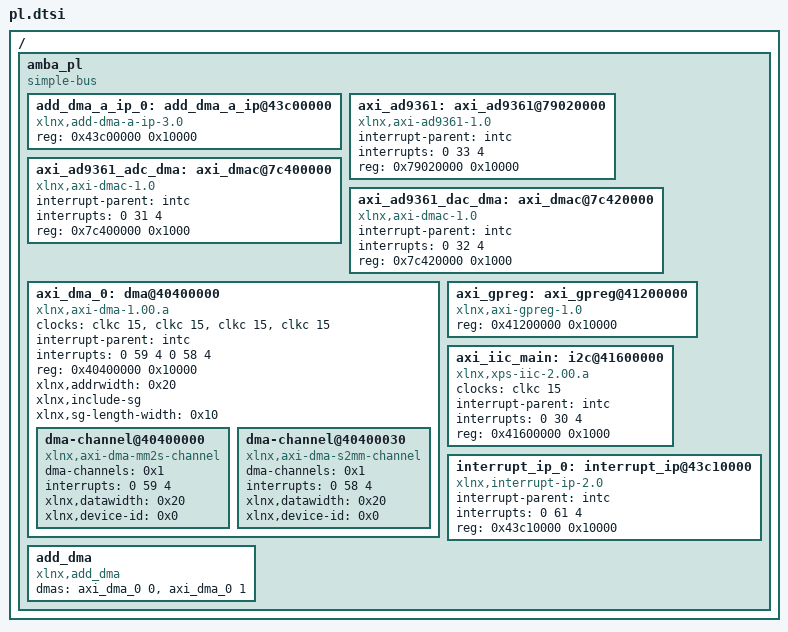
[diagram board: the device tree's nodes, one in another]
/*
 * CAUTION: This file is automatically generated by Xilinx.
 * Version:  
 * Today is: Mon May 18 16:09:08 2020
 */


/ {
	amba_pl: amba_pl {
		#address-cells = <1>;
		#size-cells = <1>;
		compatible = "simple-bus";
		ranges ;
		add_dma_a_ip_0: add_dma_a_ip@43c00000 {
			compatible = "xlnx,add-dma-a-ip-3.0";
			reg = <0x43c00000 0x10000>;
		};
		axi_ad9361: axi_ad9361@79020000 {
			compatible = "xlnx,axi-ad9361-1.0";
			interrupt-names = "gps_pps_irq";
			interrupt-parent = <&intc>;
			interrupts = <0 33 4>;
			reg = <0x79020000 0x10000>;
		};
		axi_ad9361_adc_dma: axi_dmac@7c400000 {
			compatible = "xlnx,axi-dmac-1.0";
			interrupt-names = "irq";
			interrupt-parent = <&intc>;
			interrupts = <0 31 4>;
			reg = <0x7c400000 0x1000>;
		};
		axi_ad9361_dac_dma: axi_dmac@7c420000 {
			compatible = "xlnx,axi-dmac-1.0";
			interrupt-names = "irq";
			interrupt-parent = <&intc>;
			interrupts = <0 32 4>;
			reg = <0x7c420000 0x1000>;
		};
		axi_dma_0: dma@40400000 {
			#dma-cells = <1>;
			clock-names = "s_axi_lite_aclk", "m_axi_sg_aclk", "m_axi_mm2s_aclk", "m_axi_s2mm_aclk";
			clocks = <&clkc 15>, <&clkc 15>, <&clkc 15>, <&clkc 15>;
			compatible = "xlnx,axi-dma-1.00.a";
			interrupt-names = "mm2s_introut", "s2mm_introut";
			interrupt-parent = <&intc>;
			interrupts = <0 59 4 0 58 4>;
			reg = <0x40400000 0x10000>;
			xlnx,addrwidth = <0x20>;
			xlnx,include-sg ;
			xlnx,sg-length-width = <0x10>;
			dma-channel@40400000 {
				compatible = "xlnx,axi-dma-mm2s-channel";
				dma-channels = <0x1>;
				interrupts = <0 59 4>;
				xlnx,datawidth = <0x20>;
				xlnx,device-id = <0x0>;
			};
			dma-channel@40400030 {
				compatible = "xlnx,axi-dma-s2mm-channel";
				dma-channels = <0x1>;
				interrupts = <0 58 4>;
				xlnx,datawidth = <0x20>;
				xlnx,device-id = <0x0>;
			};
		};
		axi_gpreg: axi_gpreg@41200000 {
			compatible = "xlnx,axi-gpreg-1.0";
			reg = <0x41200000 0x10000>;
		};
		axi_iic_main: i2c@41600000 {
			#address-cells = <1>;
			#size-cells = <0>;
			clock-names = "s_axi_aclk";
			clocks = <&clkc 15>;
			compatible = "xlnx,xps-iic-2.00.a";
			interrupt-names = "iic2intc_irpt";
			interrupt-parent = <&intc>;
			interrupts = <0 30 4>;
			reg = <0x41600000 0x1000>;
		};
		interrupt_ip_0: interrupt_ip@43c10000 {
			compatible = "xlnx,interrupt-ip-2.0";
			interrupt-names = "custom_interrupt";
			interrupt-parent = <&intc>;
			interrupts = <0 61 4>;
			reg = <0x43c10000 0x10000>;
		};
		add_dma {
     		compatible ="xlnx,add_dma";
    		dmas = <&axi_dma_0 0
             		&axi_dma_0 1>;
     		dma-names = "add_dma_out", "add_dma_in";
  		};
	};
};
